# WS63 register map
File version: 1.0
CPU: other r0p0, little endian, MPU, FPU, 3 interrupt priority bits
Registers are 32-bit, read-write, reset 0x0 unless marked. A register's access mark holds for its fields unless they carry their own. Offsets are from the block's base; [hi:lo] are bit positions; {n}, {i} and the like mark numbered series; 'fields as' and 'values as' point back to an identical list.

## KM — Key Management - KLAD key derivation, keyslot locking, RKP root key protection
Base 0x44112000
0x00 RKP_LOCK — Root-key-protection engine lock owner
  [2:0] km_lock_status — Lock owner: 0=idle, 1=REE, 2=TEE, 4=PCPU, 5=AIDSP
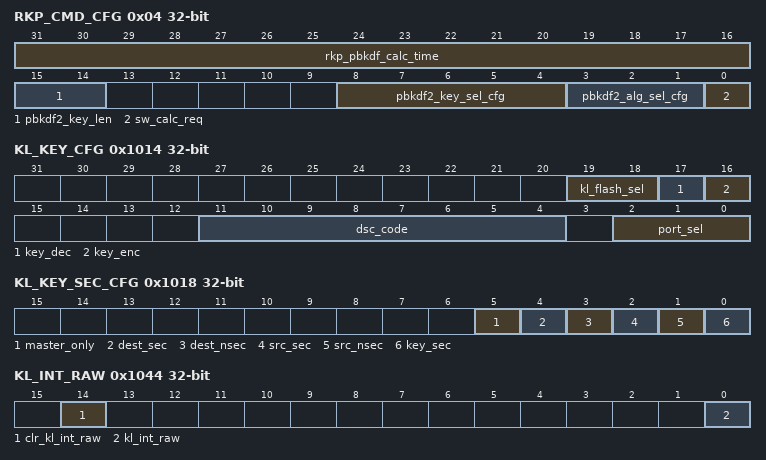
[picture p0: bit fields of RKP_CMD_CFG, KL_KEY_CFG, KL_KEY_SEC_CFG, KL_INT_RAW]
0x04 RKP_CMD_CFG — RKP PBKDF2 command and algorithm configuration
  [31:16] rkp_pbkdf_calc_time — PBKDF2 iteration count
  [15:14] pbkdf2_key_len — Hardware-key length selector; unused for the software-key path
  [8:4] pbkdf2_key_sel_cfg — PBKDF2 key source; 3 selects the software-provided key window
  [3:1] pbkdf2_alg_sel_cfg — PBKDF2 hash algorithm: 0=SHA256, 1=SHA1, 3=SHA384, 4=SHA512, 5=SM3
  [0] sw_calc_req — Start software-key PBKDF2 calculation; hardware clears on completion
0x08 KDF_ERROR ro — RKP PBKDF2 error status
  [31:0] error — Non-zero when the most recent KDF operation failed
0x10 RKP_RAW_INT — RKP raw interrupt status and write-one-to-clear acknowledgement
  [0] rkp_raw_int write-1-clears — Raw RKP completion interrupt; write one to clear
0x14 RKP_INT_ENABLE — RKP completion interrupt enable
  [0] rkp_int_enable — Enable RKP completion interrupt
0x18 RKP_INT ro — Masked RKP completion interrupt status
  [0] rkp_int — Masked RKP completion interrupt
{0x100+4i} RKP_PBKDF2_DATA[{i}] (i=0..31) wo — PBKDF2 padded salt word {i}
  [31:0] data — Padded salt word
{0x180+4i} RKP_PBKDF2_KEY[{i}] (i=0..31) wo — PBKDF2 padded password word {i}
  [31:0] data — Padded password word
{0x200+4i} RKP_PBKDF2_VAL[{i}] (i=0..15) — PBKDF2 initial-state or output word {i}
  [31:0] data — Initial hash state before start; derived key material after completion
0x1000 KL_DATA_IN_0 wo — Key data input word 0
  [31:0] data — Key data[31:0]
{0x1000+4i} KL_DATA_IN_{i} (i=1..3) — Key data input word {i}
  [31:0] data wo — Key data[{32i+31}:{32i}]
0x1010 KL_KEY_ADDR — Key address register
  [9:0] key_addr — Target key slot address
0x1014 KL_KEY_CFG — Key configuration register
  [19:18] kl_flash_sel — Flash key source select
  [17] key_dec — Key decrypt enable
  [16] key_enc — Key encrypt enable
  [11:4] dsc_code — Descriptor code
  [2:0] port_sel — Port select
0x1018 KL_KEY_SEC_CFG — Key security configuration
  [5] master_only — Master-only access
  [4] dest_sec — Destination secure
  [3] dest_nsec — Destination non-secure
  [2] src_sec — Source secure: 0=NS; 1=Secure
  [1] src_nsec — Source non-secure: 0=secure; 1=NS
  [0] key_sec — Key security: 0=NS; 1=Secure
0x1030 KL_STATE — KLAD state register
  [31:0] state ro — KLAD processing state
0x1038 KL_ERROR — KLAD error register
  [31:0] error ro — KLAD error code
0x103C KC_ERROR ro — Key controller error register
  [31:0] error — Key controller error code
0x1040 KL_INT_EN — KLAD interrupt enable
  [0] kl_int_en
0x1044 KL_INT_RAW — KLAD raw interrupt status; write one to clear
  [14] clr_kl_int_raw write-1-clears — Clear-key route completion; write one to clear
  [0] kl_int_raw write-1-clears — Common KLAD completion; write one to clear
0x1048 KL_INT — KLAD interrupt status
  [0] kl_int ro — KLAD interrupt flag
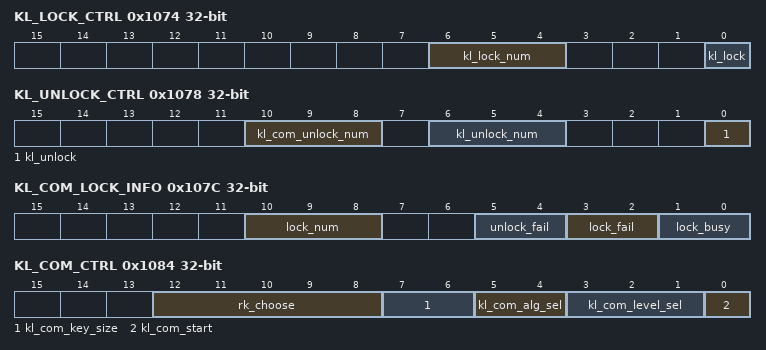
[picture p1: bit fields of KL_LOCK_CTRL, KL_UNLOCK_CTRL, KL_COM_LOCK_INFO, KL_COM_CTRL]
0x1074 KL_LOCK_CTRL — KLAD lock control
  [6:4] kl_lock_num — Lock sequence number
  [0] kl_lock wo — Lock request
0x1078 KL_UNLOCK_CTRL wo — KLAD unlock control
  [10:8] kl_com_unlock_num — Common unlock sequence number
  [6:4] kl_unlock_num — Unlock sequence number
  [0] kl_unlock — Unlock request
0x107C KL_COM_LOCK_INFO ro — KLAD common lock result
  [10:8] lock_num — Current lock sequence number
  [5:4] unlock_fail — Unlock failure state
  [3:2] lock_fail — Lock failure state
  [1:0] lock_busy — Lock operation busy state
0x1080 KL_COM_LOCK_STATUS ro — KLAD common lock owner status
  [7:0] lock_status — 0xAA means locked by the caller
0x1084 KL_COM_CTRL — KLAD common control
  [12:8] rk_choose — Root key select: 4=USD; 5=SBRK; 6=ABRK; 13=DRK; 18=PSK
  [7:6] kl_com_key_size — Key size select
  [5:4] kl_com_alg_sel — Algorithm select
  [3:1] kl_com_level_sel — Level select
  [0] kl_com_start wo — Common KDF start
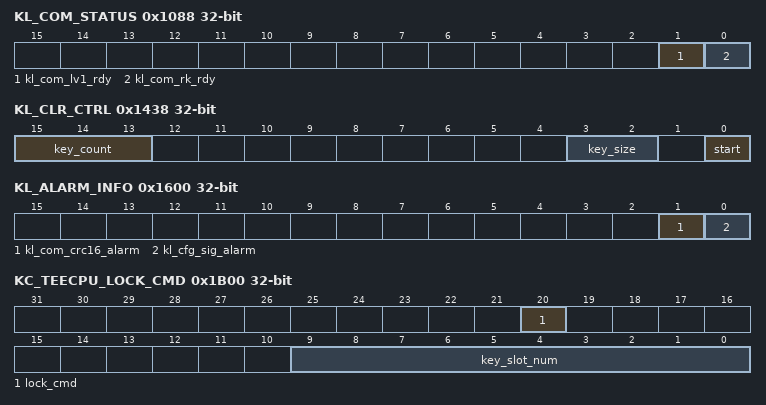
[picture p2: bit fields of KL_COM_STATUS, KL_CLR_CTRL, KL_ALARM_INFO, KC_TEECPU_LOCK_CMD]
0x1088 KL_COM_STATUS — KLAD common status
  [1] kl_com_lv1_rdy ro — Level 1 key ready
  [0] kl_com_rk_rdy ro — Root key ready
0x1438 KL_CLR_CTRL — KLAD clear-key route control
  [15:13] key_count — Software HMAC key block index
  [3:2] key_size — Key size: 1=128bit; 2=192bit; 3=256bit
  [0] start — Start clear-key route; hardware clears on completion
0x1600 KL_ALARM_INFO — KLAD alarm info register
  [1] kl_com_crc16_alarm ro — Common CRC16 alarm
  [0] kl_cfg_sig_alarm ro — Config signature alarm
0x1B00 KC_TEECPU_LOCK_CMD — TEE CPU keyslot lock command
  [20] lock_cmd wo — Lock command: 0x01=REE; 0x10=TEE; 0x100=PCPU; 0x110=AIDSP
  [9:0] key_slot_num — Key slot number
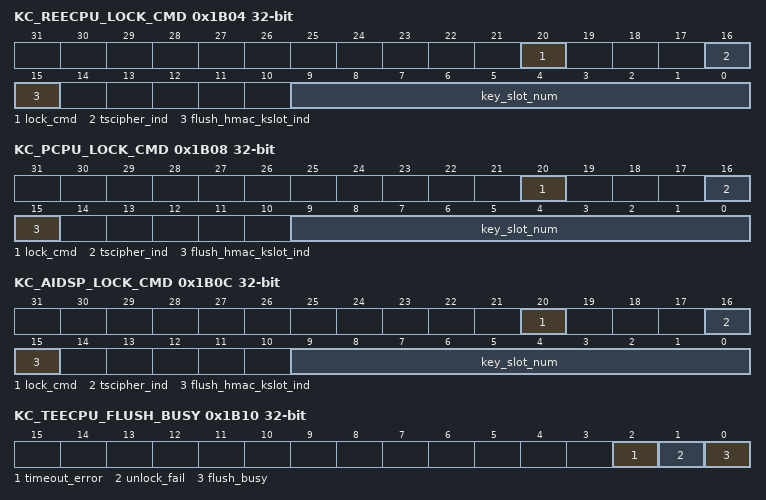
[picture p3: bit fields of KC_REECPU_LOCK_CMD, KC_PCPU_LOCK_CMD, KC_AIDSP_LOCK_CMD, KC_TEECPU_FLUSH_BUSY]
0x1B04 KC_REECPU_LOCK_CMD — REE CPU keyslot lock command
  [20] lock_cmd wo — Lock command: 1=lock; 0=unlock
  [16] tscipher_ind — TSCipher indicator
  [15] flush_hmac_kslot_ind — Keyslot type: 0=mcipher; 1=HMAC
  [9:0] key_slot_num — Key slot number
0x1B08 KC_PCPU_LOCK_CMD — PCPU keyslot lock command
  fields as KC_REECPU_LOCK_CMD
0x1B0C KC_AIDSP_LOCK_CMD — AIDSP keyslot lock command
  fields as KC_REECPU_LOCK_CMD
0x1B10 KC_TEECPU_FLUSH_BUSY ro — TEE CPU keyslot flush status
  [2] timeout_error — Last keyslot flush timed out
  [1] unlock_fail — Last keyslot unlock failed
  [0] flush_busy — Keyslot flush is in progress
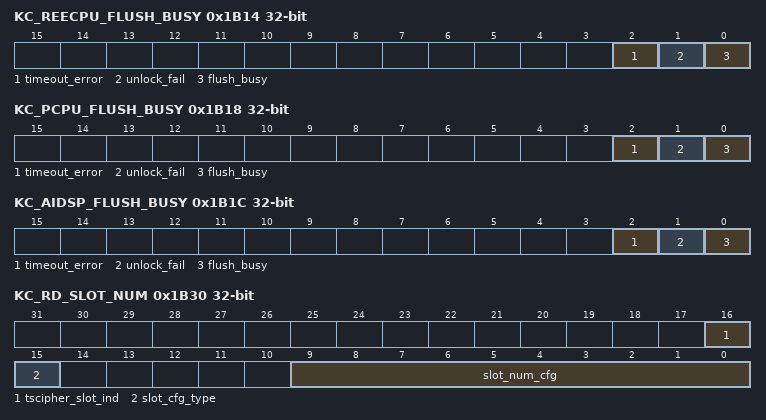
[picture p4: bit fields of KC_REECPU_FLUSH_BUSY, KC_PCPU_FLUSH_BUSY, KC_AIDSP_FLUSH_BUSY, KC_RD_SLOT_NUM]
0x1B14 KC_REECPU_FLUSH_BUSY ro — REE CPU keyslot flush status
  fields as KC_TEECPU_FLUSH_BUSY
0x1B18 KC_PCPU_FLUSH_BUSY ro — PCPU keyslot flush status
  fields as KC_TEECPU_FLUSH_BUSY
0x1B1C KC_AIDSP_FLUSH_BUSY ro — AIDSP keyslot flush status
  fields as KC_TEECPU_FLUSH_BUSY
0x1B30 KC_RD_SLOT_NUM — Keyslot query slot number selection
  [16] tscipher_slot_ind — TSCipher slot indicator
  [15] slot_cfg_type — Keyslot type: 0=mcipher; 1=HMAC
  [9:0] slot_num_cfg — Slot number to query (0-255)
0x1B34 KC_RD_LOCK_STATUS — Keyslot lock status readback
  [2:0] rd_lock_status ro — Lock status: 0=unlock; 1=REE; 2=TEE; 4=PCPU; 6=AIDSP
